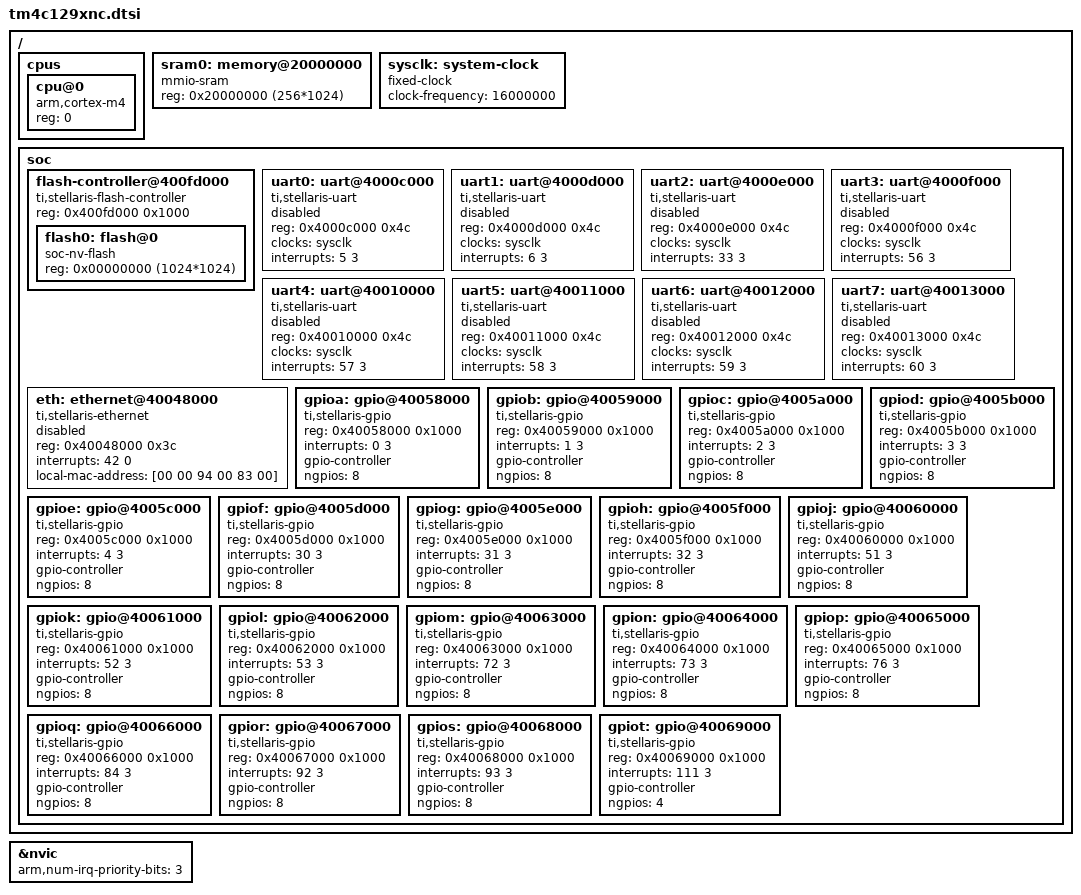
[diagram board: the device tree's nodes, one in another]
/* SPDX-License-Identifier: Apache-2.0 */

#include <arm/armv7-m.dtsi>

/ {
	cpus {
		#address-cells = <1>;
		#size-cells = <0>;

		cpu@0 {
			device_type = "cpu";
			compatible = "arm,cortex-m4";
			reg = <0>;
		};
	};

	sram0: memory@20000000 {
		compatible = "mmio-sram";
		reg = <0x20000000 (256*1024)>;
	};

	sysclk: system-clock {
		compatible = "fixed-clock";
		clock-frequency = <16000000>;
		#clock-cells = <0>;
	};

	soc {

        /* FIXME.   The Tiva flash controller uses bigger write pages than the older stellaris part */
		flash-controller@400fd000 {
			compatible = "ti,stellaris-flash-controller";
			reg = <0x400fd000 0x1000>;
			#address-cells = <1>;
			#size-cells = <1>;

			flash0: flash@0 {
				compatible = "soc-nv-flash";
				reg = <0x00000000 (1024*1024)>;
			};
		};

        /*
         The Tiva UART IP is a superset of the LM3S both appear to use the ARM UART IP
        */

		uart0: uart@4000c000 {
			compatible = "ti,stellaris-uart";
			reg = <0x4000c000 0x4c>;
			clocks = <&sysclk>;
			interrupts = <5 3>;
			status = "disabled";
		};

		uart1: uart@4000d000 {
			compatible = "ti,stellaris-uart";
			reg = <0x4000d000 0x4c>;
			clocks = <&sysclk>;
			interrupts = <6 3>;
			status = "disabled";
		};

		uart2: uart@4000e000 {
			compatible = "ti,stellaris-uart";
			reg = <0x4000e000 0x4c>;
			clocks = <&sysclk>;
			interrupts = <33 3>;
			status = "disabled";
		};

		uart3: uart@4000f000 {
			compatible = "ti,stellaris-uart";
			reg = <0x4000f000 0x4c>;
			clocks = <&sysclk>;
			interrupts = <56 3>;
			status = "disabled";
		};

		uart4: uart@40010000 {
			compatible = "ti,stellaris-uart";
			reg = <0x40010000 0x4c>;
			clocks = <&sysclk>;
			interrupts = <57 3>;
			status = "disabled";
		};

		uart5: uart@40011000 {
			compatible = "ti,stellaris-uart";
			reg = <0x40011000 0x4c>;
			clocks = <&sysclk>;
			interrupts = <58 3>;
			status = "disabled";
		};

		uart6: uart@40012000 {
			compatible = "ti,stellaris-uart";
			reg = <0x40012000 0x4c>;
			clocks = <&sysclk>;
			interrupts = <59 3>;
			status = "disabled";
		};

		uart7: uart@40013000 {
			compatible = "ti,stellaris-uart";
			reg = <0x40013000 0x4c>;
			clocks = <&sysclk>;
			interrupts = <60 3>;
			status = "disabled";
		};


		eth: ethernet@40048000 {
			compatible = "ti,stellaris-ethernet";
			reg = <0x40048000 0x3c>;
			interrupts = <42 0>;
			status = "disabled";
			local-mac-address = [00 00 94 00 83 00];
		};

        /* The Tiva GPIOs are a superset of the LM3S GPIOs */
        /* Unlike the LM3S, they're available via AHB      */
		gpioa: gpio@40058000 { /* Port A */
			compatible = "ti,stellaris-gpio";
			reg = <0x40058000 0x1000>;
			interrupts = <0 3>;
			gpio-controller;
			#gpio-cells = <2>;
			ngpios = <8>;
		};

		gpiob: gpio@40059000 { /* Port B */
			compatible = "ti,stellaris-gpio";
			reg = <0x40059000 0x1000>;
			interrupts = <1 3>;
			gpio-controller;
			#gpio-cells = <2>;
			ngpios = <8>;
		};

		gpioc: gpio@4005a000 { /* Port C */
			compatible = "ti,stellaris-gpio";
			reg = <0x4005a000 0x1000>;
			interrupts = <2 3>;
			gpio-controller;
			#gpio-cells = <2>;
			ngpios = <8>;
		};

		gpiod: gpio@4005b000 { /* Port D */
			compatible = "ti,stellaris-gpio";
			reg = <0x4005b000 0x1000>;
			interrupts = <3 3>;
			gpio-controller;
			#gpio-cells = <2>;
			ngpios = <8>;
		};

		gpioe: gpio@4005c000 { /* Port E */
			compatible = "ti,stellaris-gpio";
			reg = <0x4005c000 0x1000>;
			interrupts = <4 3>;
			gpio-controller;
			#gpio-cells = <2>;
			ngpios = <8>;
		};

		gpiof: gpio@4005d000 { /* Port F */
			compatible = "ti,stellaris-gpio";
			reg = <0x4005d000 0x1000>;
			interrupts = <30 3>;
			gpio-controller;
			#gpio-cells = <2>;
			ngpios = <8>;
		};

		gpiog: gpio@4005e000 { /* Port G */
			compatible = "ti,stellaris-gpio";
			reg = <0x4005e000 0x1000>;
			interrupts = <31 3>;
			gpio-controller;
			#gpio-cells = <2>;
			ngpios = <8>;
		};

		gpioh: gpio@4005f000 { /* Port H */
			compatible = "ti,stellaris-gpio";
			reg = <0x4005f000 0x1000>;
			interrupts = <32 3>;
			gpio-controller;
			#gpio-cells = <2>;
			ngpios = <8>;
		};

		gpioj: gpio@40060000 { /* Port J */
			compatible = "ti,stellaris-gpio";
			reg = <0x40060000 0x1000>;
			interrupts = <51 3>;
			gpio-controller;
			#gpio-cells = <2>;
			ngpios = <8>;
		};

		gpiok: gpio@40061000 { /* Port K */
			compatible = "ti,stellaris-gpio";
			reg = <0x40061000 0x1000>;
			interrupts = <52 3>;
			gpio-controller;
			#gpio-cells = <2>;
			ngpios = <8>;
		};

		gpiol: gpio@40062000 { /* Port L */
			compatible = "ti,stellaris-gpio";
			reg = <0x40062000 0x1000>;
			interrupts = <53 3>;
			gpio-controller;
			#gpio-cells = <2>;
			ngpios = <8>;
		};

		gpiom: gpio@40063000 { /* Port M */
			compatible = "ti,stellaris-gpio";
			reg = <0x40063000 0x1000>;
			interrupts = <72 3>;
			gpio-controller;
			#gpio-cells = <2>;
			ngpios = <8>;
		};

		gpion: gpio@40064000 { /* Port N */
			compatible = "ti,stellaris-gpio";
			reg = <0x40064000 0x1000>;
			interrupts = <73 3>;
			gpio-controller;
			#gpio-cells = <2>;
			ngpios = <8>;
		};

		gpiop: gpio@40065000 { /* Port P */
			compatible = "ti,stellaris-gpio";
			reg = <0x40065000 0x1000>;
			interrupts = <76 3>;
			gpio-controller;
			#gpio-cells = <2>;
			ngpios = <8>;
		};

		gpioq: gpio@40066000 { /* Port Q */
			compatible = "ti,stellaris-gpio";
			reg = <0x40066000 0x1000>;
			interrupts = <84 3>;
			gpio-controller;
			#gpio-cells = <2>;
			ngpios = <8>;
		};

		gpior: gpio@40067000 { /* Port R */
			compatible = "ti,stellaris-gpio";
			reg = <0x40067000 0x1000>;
			interrupts = <92 3>;
			gpio-controller;
			#gpio-cells = <2>;
			ngpios = <8>;
		};

		gpios: gpio@40068000 { /* Port S */
			compatible = "ti,stellaris-gpio";
			reg = <0x40068000 0x1000>;
			interrupts = <93 3>;
			gpio-controller;
			#gpio-cells = <2>;
			ngpios = <8>;
		};

		gpiot: gpio@40069000 { /* Port T */
			compatible = "ti,stellaris-gpio";
			reg = <0x40069000 0x1000>;
			interrupts = <111 3>;
			gpio-controller;
			#gpio-cells = <2>;
			ngpios = <4>;
		};

	};
};

&nvic {
	arm,num-irq-priority-bits = <3>;
};
